# psoc4hv144k register map
Vendor: Infineon Technologies; Series: PSOC4HV144K; File version: 1.0
CPU: CM0PLUS r0p1, little endian, MPU, no FPU, VTOR, 2 interrupt priority bits, 25 interrupts
Registers are 32-bit, read-write, reset 0x0 unless marked. A register's access mark holds for its fields unless they carry their own. Offsets are from the block's base; [hi:lo] are bit positions.

## SPCIF — Flash Control Interface
Base 0x40110000
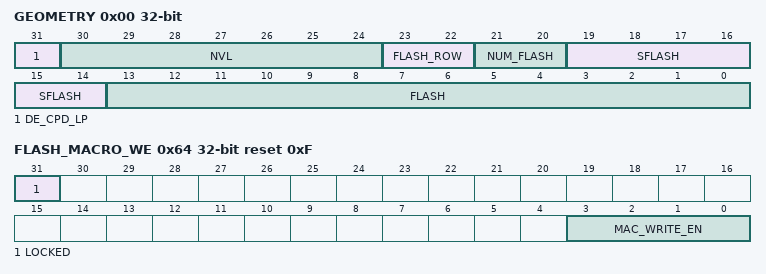
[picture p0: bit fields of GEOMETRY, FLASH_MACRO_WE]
0x00 GEOMETRY (reset mask 0x80000000) — Flash/NVL geometry information
  [31] DE_CPD_LP — 0': SRAM busy wait loop has not been copied. '1': Busy wait loop has been written into SRAM.
  [30:24] NVL ro — NVLatch size in Byte multiples (chip dependent): '0': 0 Bytes '1': 1 Byte ... '127': 127 Bytes
  [23:22] FLASH_ROW ro — Page size in 64 Byte multiples (chip dependent): '0': 64 byte '1': 128 byte '2': 192 byte '3': 256 byte The page size is used to determine the number of Bytes in a page for Flash page based operations (e.g. PGM_PAGE). Note: the field name FLASH_ROW is misleading, as this field specifies the number of Bytes in a page, rather than the number of Bytes in a row. In a single plane flash macro architecture, a page consists of a single row. However, in a multi plane flash macro architecture, a page consists of multiple rows from different planes.
  [21:20] NUM_FLASH ro — Number of flash macros (chip dependent): '0': 1 flash macro '1': 2 flash macros '2': 3 flash macros '3': 4 flash macros
  [19:14] SFLASH ro — Supervisory flash capacity in 256 Byte multiples (chip dependent). If multiple flash macros are present, this field provides the supervisory flash capacity of all flash macros together: '0': 256 Bytes. '1': 2*256 Bytes. ... '63': 64*256 Bytes.
  [13:0] FLASH ro — Regular flash capacity in 256 Byte multiples (chip dependent). If multiple flash macros are present, this field provides the flash capacity of all flash macros together: '0': 256 Bytes. '1': 2*256 Bytes. ... '16383': 16384*256 Bytes.
0x1C NVL_WR_DATA — NVL write data register
  [7:0] DATA — Data to be written to NVLatch array
0x60 FLASH_LOCK wo
  [31:0] KEY — Write Only register that locks/unlocks access to the FLASH MACRO_WE register by writing a key value to the register. The Key is the 32 bit value '0xF56B3A81'. When this specific bit pattern is written to the register, write access to FLASH_MACRO_WE is toggled between locked and unlocked. The bit FLASH_MACRO_WE.LOCKED toggles upon receipt of the required key value.
0x64 FLASH_MACRO_WE reset 0xF — Flash Macro Write Enable
  [31] LOCKED ro — When set indicates that write access to FLASH_MACRO_WE.MAC_WRITE_EN is blocked. The value of this bit toggles when the key value is written into FLASH_LOCK.KEY.
  [3:0] MAC_WRITE_EN — Access control to Flash Macros Write Access. This is a bit mask where each bit controls Program/Erase Access to the corresponding Macro. When the bit is set to '1' then the Macro may be programmed/erased, when the bit is set to '0', the Macro content is locked. The content of this register may only be changed when FLASH_MACRO_WE.LOCKED is '0'.
0x7F0 INTR — SPCIF interrupt request register
  [0] TIMER write-1-clears — Timer counter value reaches '0'. Set to '1', when event is detected. Write INTR field with '1', to clear bit. Write INTR_SET field with '1', to set bit.
0x7F4 INTR_SET — SPCIF interrupt set request register
  [0] TIMER write-1-sets — Write INTR_SET field with '1' to set corresponding INTR field.
0x7F8 INTR_MASK — SPCIF interrupt mask register
  [0] TIMER — Mask for corresponding field in INTR register.
0x7FC INTR_MASKED ro — SPCIF interrupt masked request register
  [0] TIMER — Logical and of corresponding request and mask fields.

## SPCIF1 — Flash Control Interface
Base 0x40120000
Registers as SPCIF; these are added or differ:
0x7F0 INTR — SPCIF interrupt request register
  [0] TIMER write-1-clears — Timer counter value reaches '0'. Set to '1', when event is detected. Write INTR field with '1', to clear bit. Write INTR_SET field with '1', to set bit.
0x7F4 INTR_SET — SPCIF interrupt set request register
  [0] TIMER write-1-sets — Write INTR_SET field with '1' to set corresponding INTR field.
0x7F8 INTR_MASK — SPCIF interrupt mask register
  [0] TIMER — Mask for corresponding field in INTR register.
0x7FC INTR_MASKED ro — SPCIF interrupt masked request register
  [0] TIMER — Logical and of corresponding request and mask fields.
